# Generic_ARMv7M register map
Vendor: ARM Ltd.; Series: ARMv7-M architecture (Cortex-M3 / Cortex-M4 / Cortex-M7 / SC300); File version: 1.0
CPU: CM3 r0p1, little endian, no MPU, no FPU, VTOR, 3 interrupt priority bits
Registers are 32-bit, read-write, reset 0x0 unless marked. A register's access mark holds for its fields unless they carry their own. Offsets are from the block's base; [hi:lo] are bit positions; {n}, {i} and the like mark numbered series.

## SCB — System Control Block, ARMv7-M register set. Verified against CMSIS_6 core_cm3.h/core_cm4.h/core_cm7.h defines (all three are identical at the SCB level -- the FPU-related extras live in a separate optional FPU block, not shown here, since plain Cortex-M3 has no FPU at all). ID_PFR/ID_DFR/ID_AFR/ID_MMFR/ID_ISAR are read-only ID registers whose exact values are implementation specific (renamed from PFR/DFR/ADR/MMFR/ISAR in CMSIS_6, to match the naming CMSIS has always used for the same registers on ARMv8-M). CMSIS_6's SCB_Type also declares an alias of NVIC's STIR at offset 0x200 (same physical register as NVIC->STIR, at 0xE000EF00) -- not duplicated here, STIR is modeled once, under NVIC, same treatment as SAU/SCB's SFSR/SFAR aliasing on the ARMv8-M Mainline file.
Base 0xE000ED00
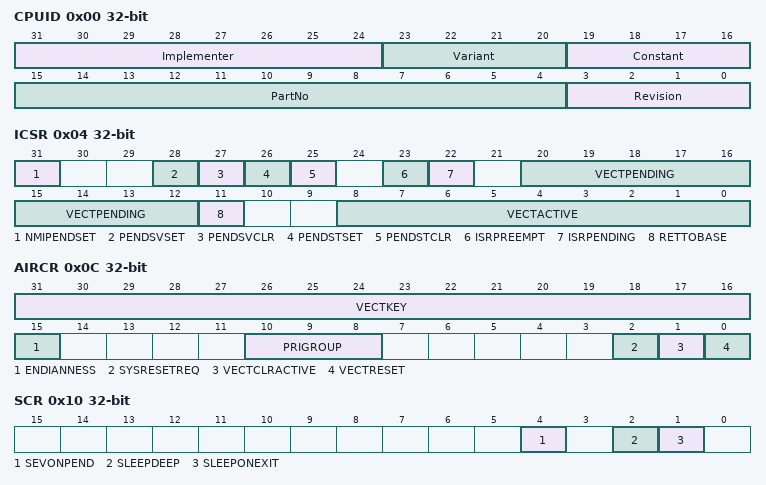
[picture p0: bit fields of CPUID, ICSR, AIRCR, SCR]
0x00 CPUID ro — CPUID Base Register. Reset value is implementation/revision specific.
  [31:24] Implementer — 0x41 = 'A' = ARM
  [23:20] Variant — Implementation specific variant number
  [19:16] Constant — Reads as 0xC for ARMv6-M, 0xF for ARMv7-M/ARMv8-M
  [15:4] PartNo — Implementation specific part number
  [3:0] Revision — Implementation/revision specific (e.g. r0p0 = 0x0)
0x04 ICSR — Interrupt Control and State Register
  [31] NMIPENDSET, [28] PENDSVSET, [27] PENDSVCLR wo, [26] PENDSTSET, [25] PENDSTCLR wo, [23] ISRPREEMPT ro, [22] ISRPENDING ro, [20:12] VECTPENDING, [11] RETTOBASE ro, [8:0] VECTACTIVE
0x08 VTOR — Vector Table Offset Register
  [31:7] TBLOFF
0x0C AIRCR — Application Interrupt and Reset Control Register
  [31:16] VECTKEY — Write 0x05FA to permit the write; reads as 0xFA05
  [15] ENDIANNESS ro — Renamed from ENDIANESS in CMSIS_6 (kept as a deprecated alias there)
  [10:8] PRIGROUP — Interrupt priority grouping
  [2] SYSRESETREQ
  [1] VECTCLRACTIVE — Reserved for debug use
  [0] VECTRESET — Reserved for debug use
0x10 SCR — System Control Register
  [4] SEVONPEND, [2] SLEEPDEEP, [1] SLEEPONEXIT
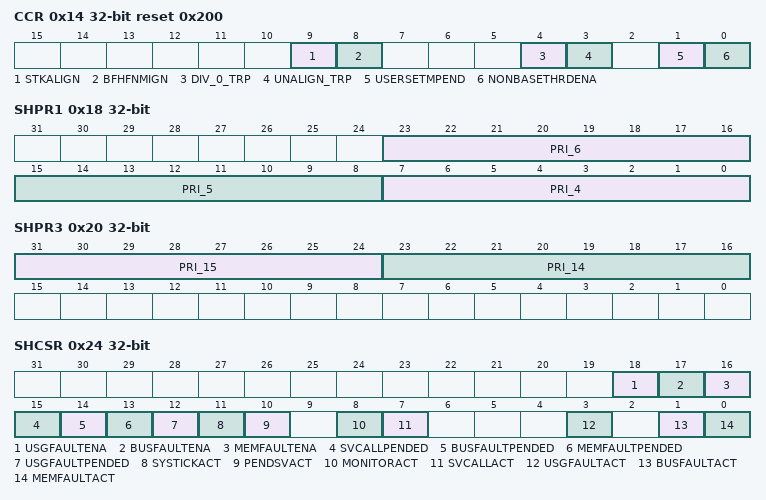
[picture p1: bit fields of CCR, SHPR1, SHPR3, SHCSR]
0x14 CCR reset 0x200 — Configuration and Control Register
  [9] STKALIGN, [8] BFHFNMIGN, [4] DIV_0_TRP, [3] UNALIGN_TRP, [1] USERSETMPEND, [0] NONBASETHRDENA
0x18 SHPR1 — System Handler Priority Register 1
  [23:16] PRI_6 — UsageFault
  [15:8] PRI_5 — BusFault
  [7:0] PRI_4 — MemManage fault
0x1C SHPR2 — System Handler Priority Register 2
  [31:24] PRI_11 — SVCall
0x20 SHPR3 — System Handler Priority Register 3
  [31:24] PRI_15 — SysTick
  [23:16] PRI_14 — PendSV
0x24 SHCSR — System Handler Control and State Register
  [18] USGFAULTENA, [17] BUSFAULTENA, [16] MEMFAULTENA, [15] SVCALLPENDED, [14] BUSFAULTPENDED, [13] MEMFAULTPENDED, [12] USGFAULTPENDED, [11] SYSTICKACT, [10] PENDSVACT, [8] MONITORACT, [7] SVCALLACT, [3] USGFAULTACT, [1] BUSFAULTACT, [0] MEMFAULTACT
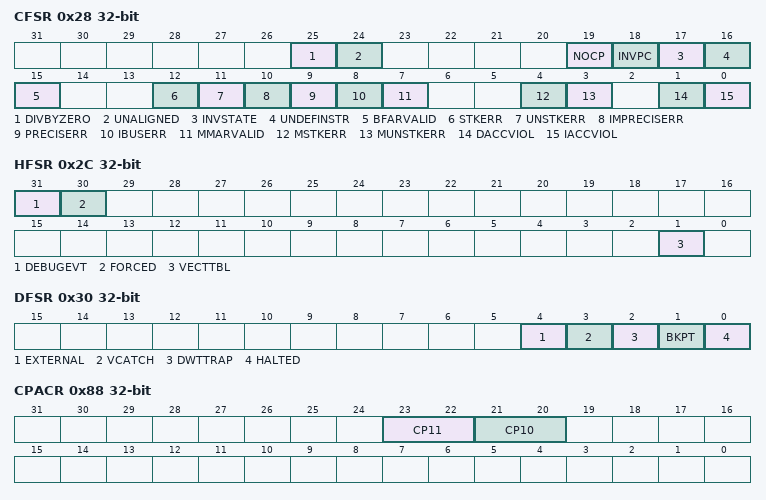
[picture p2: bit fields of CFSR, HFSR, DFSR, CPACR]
0x28 CFSR — Configurable Fault Status Register = MMFSR[7:0] | BFSR[15:8] | UFSR[31:16]
  [25] DIVBYZERO — UFSR
  [24] UNALIGNED — UFSR
  [19] NOCP — UFSR
  [18] INVPC — UFSR
  [17] INVSTATE — UFSR
  [16] UNDEFINSTR — UFSR
  [15] BFARVALID ro — BFSR
  [12] STKERR — BFSR
  [11] UNSTKERR — BFSR
  [10] IMPRECISERR — BFSR
  [9] PRECISERR — BFSR
  [8] IBUSERR — BFSR
  [7] MMARVALID ro — MMFSR
  [4] MSTKERR — MMFSR
  [3] MUNSTKERR — MMFSR
  [1] DACCVIOL — MMFSR
  [0] IACCVIOL — MMFSR
0x2C HFSR — HardFault Status Register
  [31] DEBUGEVT, [30] FORCED, [1] VECTTBL
0x30 DFSR — Debug Fault Status Register
  [4] EXTERNAL, [3] VCATCH, [2] DWTTRAP, [1] BKPT, [0] HALTED
0x34 MMFAR — MemManage Fault Address Register, valid only when CFSR.MMARVALID is set
  [31:0] ADDRESS
0x38 BFAR — BusFault Address Register, valid only when CFSR.BFARVALID is set
  [31:0] ADDRESS
0x3C AFSR — Auxiliary Fault Status Register, implementation defined
  [31:0] IMPDEF
{0x40+4i} ID_PFR{i} (i=0..1) ro — Processor Feature Register, implementation defined
0x48 ID_DFR ro — Debug Feature Register, implementation defined
0x4C ID_AFR ro — Auxiliary Feature Register, implementation defined
{0x50+4i} ID_MMFR{i} (i=0..3) ro — Memory Model Feature Register, implementation defined
{0x60+4i} ID_ISAR{i} (i=0..4) ro — Instruction Set Attributes Register, implementation defined
0x88 CPACR — Coprocessor Access Control Register. Present architecturally on every ARMv7-M core; only relevant when a coprocessor (typically the optional FPU on Cortex-M4/M7) is actually implemented -- reads as 0 / has no effect otherwise.
  [23:22] CP11 — FPU access privileges -- only meaningful if an FPU is implemented (Cortex-M4/M7)
  [21:20] CP10 — FPU access privileges -- only meaningful if an FPU is implemented (Cortex-M4/M7)
